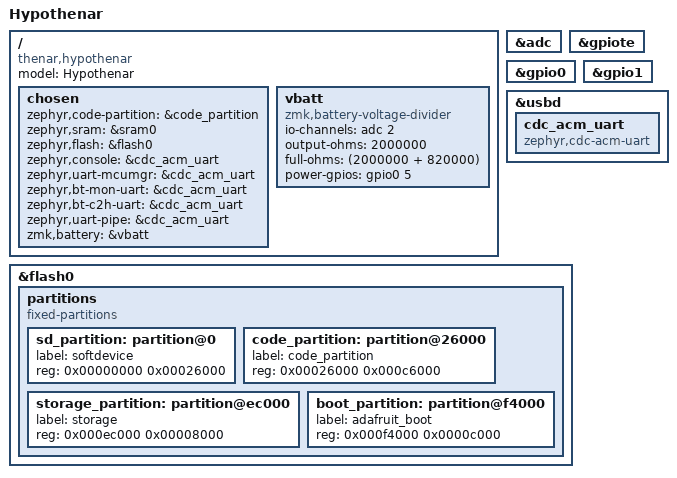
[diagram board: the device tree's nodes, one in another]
// SPDX-License-Identifier: MIT
//
// Hypothenar: MS88SF3-nRF52840 module on a custom keyboard PCB.
//
// Pin assignments are keyed off ergogen/config.yaml's MS88SF3 pad map. The
// nRF52840 GPIOs used below (I2C SDA=P0.26 / SCL=P0.27, I2C_RESET=P0.31,
// INTA MCP_A=P0.30 / MCP_B=P0.02, BATT_ADC=P0.04 / enable P0.05, encoder
// A=P0.29 / B=P0.28, SWD, USB) match the ergogen pad->net assignments
// pad-for-pad. THE MS88SF3 PAD->nRF52840-PIN MAP IS DATASHEET-VERIFIED
// (2026-07, Minew MS88SF3 rev-K, section 3 Pin Description) - all GPIOs
// above confirmed against the pad diagram. Keep this file and
// ergogen/config.yaml in lockstep on any future change. (The old comment
// here listed P14=USB_DP/P20=I2C_SCL/etc. - that was stale and WRONG.)

/dts-v1/;
#include <nordic/nrf52840_qiaa.dtsi>
#include "hypothenar-pinctrl.dtsi"

/ {
    model = "Hypothenar";
    compatible = "thenar,hypothenar";

    chosen {
        zephyr,code-partition = &code_partition;
        zephyr,sram = &sram0;
        zephyr,flash = &flash0;
        zephyr,console = &cdc_acm_uart;
        zephyr,uart-mcumgr = &cdc_acm_uart;
        zephyr,bt-mon-uart = &cdc_acm_uart;
        zephyr,bt-c2h-uart = &cdc_acm_uart;
        zephyr,uart-pipe = &cdc_acm_uart;
        zmk,battery = &vbatt;
    };

    // Battery voltage divider on a SAADC channel. Update the gpios pin
    // once the PCB routing pins this to a specific MS88SF3 pad.
    vbatt: vbatt {
        compatible = "zmk,battery-voltage-divider";
        io-channels = <&adc 2>;  // AIN2 = P0.04, MS88SF3 pad 16
        output-ohms = <2000000>;
        full-ohms = <(2000000 + 820000)>;
        power-gpios = <&gpio0 5 GPIO_ACTIVE_HIGH>;  // P0.05, pad 15
    };
};

&adc {
    status = "okay";
};

&gpiote {
    status = "okay";
};

&gpio0 {
    status = "okay";
};

&gpio1 {
    status = "okay";
};

// I2C / MCP23017 expanders REMOVED (2026-07): switches now scan as a
// direct diode matrix off gpio0 (see the shield's hypothenar.dtsi
// kscan_matrix). P0.26/P0.27/P0.30/P0.31/P0.02 that were the I2C bus +
// interrupts are now matrix row-sense lines.

&usbd {
    status = "okay";
    cdc_acm_uart: cdc_acm_uart {
        compatible = "zephyr,cdc-acm-uart";
    };
};

zephyr_udc0: &usbd {
    status = "okay";
};

&flash0 {
    partitions {
        compatible = "fixed-partitions";
        #address-cells = <1>;
        #size-cells = <1>;

        // Match nice_nano_v2 / Adafruit nRF52 bootloader layout so the
        // same UF2 path works.
        sd_partition: partition@0 {
            label = "softdevice";
            reg = <0x00000000 0x00026000>;
        };
        code_partition: partition@26000 {
            label = "code_partition";
            reg = <0x00026000 0x000c6000>;
        };
        storage_partition: partition@ec000 {
            label = "storage";
            reg = <0x000ec000 0x00008000>;
        };
        boot_partition: partition@f4000 {
            label = "adafruit_boot";
            reg = <0x000f4000 0x0000c000>;
        };
    };
};

